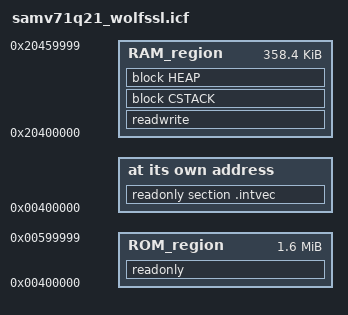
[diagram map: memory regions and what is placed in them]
/*
 * A simple example for evaluation purposes written from scratch by wolfSSL Inc
 */

/*###ICF### ****/
/*-Editor annotation file-*/
/* IcfEditorFile="$TOOLKIT_DIR$\config\ide\IcfEditor\cortex_v1_0.xml" */
/*-Specials-*/
define symbol __ICFEDIT_intvec_start__     = 0x00400000;
/*-Memory Regions-*/
define symbol __ICFEDIT_region_RAM_start__ = 0x20400000;
define symbol __ICFEDIT_region_RAM_end__   = 0x20459999;
define symbol __ICFEDIT_region_ROM_start__ = 0x00400000;
define symbol __ICFEDIT_region_ROM_end__   = 0x00599999;
/*-Sizes-*/
define symbol __ICFEDIT_size_cstack__      = 0x400;
define symbol __ICFEDIT_size_heap__        = 0x13000;
/**** ###ICF###*/

define memory mem with size = 4G;
define region RAM_region = mem:[from __ICFEDIT_region_RAM_start__ to __ICFEDIT_region_RAM_end__];
define region ROM_region = mem:[from __ICFEDIT_region_ROM_start__ to __ICFEDIT_region_ROM_end__];

define block CSTACK with alignment = 8, size = __ICFEDIT_size_cstack__ { };
define block HEAP with alignment = 8, size = __ICFEDIT_size_heap__ { };

initialize by copy { readwrite };
do not initialize { section .noinit };

place at address mem:__ICFEDIT_intvec_start__ { readonly section .intvec };
place in ROM_region { readonly };
place in RAM_region { readwrite, block CSTACK, block HEAP };

